# key_manager: IP-XACT component
VLNV tenstorrent.com:ocah:key_manager:1.0

## Address spaces and blocks
key_manager.rom: base 'h0, range 'h4000, width 32, memory
key_manager.sram: base 'h8000, range 'h8000, width 32, memory
key_manager.mailbox_km: base 'h10000, range 'h1c, width 32
key_manager.otp_efuse_map: base 'h11000, range 'h400, width 256
key_manager.otp_efuse_ctrl: base 'h11400, range 'h24, width 32
key_manager.otp_efuse_mmr: base 'h11500, range 'h74, width 32
key_manager.kpv: base 'h12000, range 'h1108, width 32
key_manager.kmcsr: base 'h14000, range 'h4c0, width 32
key_manager.drbg_sampler: base 'h15000, range 'h10, width 32
key_manager.otbn_wrapper_key: base 'h18000, range 'h64, width 32
key_manager.aes_wrapper_key: base 'h19000, range 'h44, width 32
key_manager.kmac_wrapper_key: base 'h1a000, range 'h44, width 32
key_manager.hmac_wrapper_key: base 'h1b000, range 'h44, width 32
key_manager.abr_wrapper_key: base 'h1c000, range 'h42c, width 32

## Registers
Registers are 32-bit, read-only, no defined reset value unless marked. A register's access mark holds for its fields unless they carry their own. Offsets are from the block's base; lines under a group give offsets from that group; [hi:lo] are bit positions; {n}, {i} and the like mark numbered series; 'fields as' and 'values as' point back to an identical list; <NAME> marks a mode.

## key_manager.mailbox_km — Register interface for KM CPU to access mailbox (write to outbound FIFO, read from inbound FIFO)
Base 0x00010000
0x00 KM_WRITE_DATA wo reset 0x0 — Write data to outbound FIFO (KM→SEP messages)
  [31:0] data — 32-bit data word to write to outbound FIFO
0x04 KM_WRITE_SEPARATOR access per field reset 0x0 — Write 1 to set message separator on next outbound (KM→SEP) write. Cleared by hardware when that write completes.
  [0] set rw — Write 1 to set message separator on next outbound write. Cleared by hardware when that write completes.
0x08 KM_READ_DATA reset 0x0 — Read data from inbound FIFO (SEP→KM messages)
  [31:0] data — 32-bit data word read from inbound FIFO
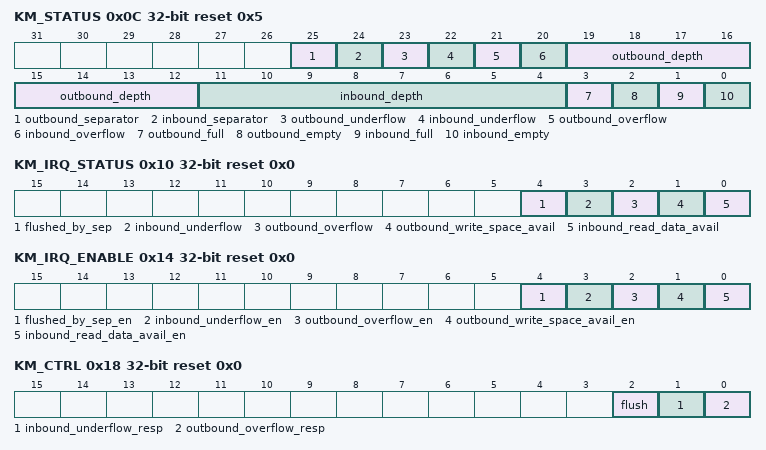
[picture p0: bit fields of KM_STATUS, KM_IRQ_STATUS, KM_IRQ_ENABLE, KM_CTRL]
0x0C KM_STATUS access per field reset 0x5 — FIFO status information
  [25] outbound_separator ro — Message separator: 1 if the last word read from outbound FIFO had the separator bit set (last word of message). Read-only, not sticky.
  [24] inbound_separator ro — Message separator: 1 if the last word read from inbound FIFO had the separator bit set (last word of message). Read-only, not sticky.
  [23] outbound_underflow rw write-1-clears — Outbound FIFO underflow detected (read attempted when empty). Sticky, write 1 to clear.
  [22] inbound_underflow rw write-1-clears — Inbound FIFO underflow detected (read attempted when empty). Sticky, write 1 to clear.
  [21] outbound_overflow rw write-1-clears — Outbound FIFO overflow detected (write attempted when full). Sticky, write 1 to clear.
  [20] inbound_overflow rw write-1-clears — Inbound FIFO overflow detected (write attempted when full). Sticky, write 1 to clear.
  [19:12] outbound_depth ro — Outbound FIFO fill level (number of words in FIFO)
  [11:4] inbound_depth ro — Inbound FIFO fill level (number of words in FIFO)
  [3] outbound_full ro — Outbound FIFO is full (cannot write more data)
  [2] outbound_empty ro — Outbound FIFO is empty (no data available for SEP to read)
  [1] inbound_full ro — Inbound FIFO is full
  [0] inbound_empty ro — Inbound FIFO is empty (no data available for KM to read)
0x10 KM_IRQ_STATUS access per field reset 0x0 — Interrupt status register
  [4] flushed_by_sep rw write-1-clears — SEP performed a mailbox flush. Sticky, write 1 to clear.
  [3] inbound_underflow rw write-1-clears — Inbound FIFO underflow detected. Sticky, write 1 to clear.
  [2] outbound_overflow rw write-1-clears — Outbound FIFO overflow detected. Sticky, write 1 to clear.
  [1] outbound_write_space_avail ro — Outbound FIFO has space available for KM to write (level-sensitive). 1 = space available, 0 = full.
  [0] inbound_read_data_avail ro — Inbound FIFO has data available for KM to read (level-sensitive). 1 = data available, 0 = empty.
0x14 KM_IRQ_ENABLE access per field reset 0x0 — Interrupt enable register for KM CPU
  [4] flushed_by_sep_en rw — Enable interrupt to KM when SEP performs a mailbox flush
  [3] inbound_underflow_en rw — Enable interrupt to KM when inbound FIFO underflow is detected
  [2] outbound_overflow_en rw — Enable interrupt to KM when outbound FIFO overflow is detected
  [1] outbound_write_space_avail_en rw — Enable interrupt to KM when outbound FIFO has space available (KM->SEP messages)
  [0] inbound_read_data_avail_en rw — Enable interrupt to KM when inbound FIFO has data available (SEP->KM messages)
0x18 KM_CTRL access per field reset 0x0 — Control register for mailbox behavior configuration
  [2] flush rw — Write 1 to flush all mailbox FIFOs (inbound and outbound). Cleared by hardware when flush completes.
  [1] inbound_underflow_resp rw — Response type for inbound FIFO underflow: 0=SLVERR (default), 1=OKAY
  [0] outbound_overflow_resp rw — Response type for outbound FIFO overflow: 0=SLVERR (default), 1=OKAY

## key_manager.otp_efuse_map — Per-field write-lock and read-lock registers for the SEP eFuse map.
Base 0x00011000
0x00 LOCKS 64-bit rw reset 0x0
  [63] SEP_SYS_ID_READ_LOCK write-1-sets — sep_sys_id_read_lock (slot 31): when set, SEP_SYS_ID is not read-able.
  [62] SEP_SYS_ID_WRITE_LOCK write-1-sets — sep_sys_id_write_lock (slot 31): when set, SEP_SYS_ID is not write-able.
  [61] SEP_SIP_ID_READ_LOCK write-1-sets — sep_sip_id_read_lock (slot 30): when set, SEP_SIP_ID is not read-able.
  [60] SEP_SIP_ID_WRITE_LOCK write-1-sets — sep_sip_id_write_lock (slot 30): when set, SEP_SIP_ID is not write-able.
  [59] SEP_CHIPLET_ID_READ_LOCK write-1-sets — sep_chiplet_id_read_lock (slot 29): when set, SEP_CHIPLET_ID is not read-able.
  [58] SEP_CHIPLET_ID_WRITE_LOCK write-1-sets — sep_chiplet_id_write_lock (slot 29): when set, SEP_CHIPLET_ID is not write-able.
  [57] SIP_PUBK_PQC_HASH1_READ_LOCK write-1-sets — sip_pubk_pqc_hash1_read_lock, when set, this field is not read-able (neither the eFuse nor the shadow register)
  [56] SIP_PUBK_PQC_HASH1_WRITE_LOCK write-1-sets — sip_pubk_pqc_hash1_write_lock, when set, this field is not write-able (neither the eFuse nor the shadow register)
  [55] SIP_PUBK_HASH1_READ_LOCK write-1-sets — sip_pubk_hash1_read_lock, when set, this field is not read-able (neither the eFuse nor the shadow register)
  [54] SIP_PUBK_HASH1_WRITE_LOCK write-1-sets — sip_pubk_hash1_write_lock, when set, this field is not write-able (neither the eFuse nor the shadow register)
  [53] SYS_PUBK_PQC_HASH_READ_LOCK write-1-sets — sys_pubk_pqc_hash_read_lock, when set, this field is not read-able (neither the eFuse nor the shadow register)
  [52] SYS_PUBK_PQC_HASH_WRITE_LOCK write-1-sets — sys_pubk_pqc_hash_write_lock, when set, this field is not write-able (neither the eFuse nor the shadow register)
  [51] SIP_PUBK_PQC_HASH0_READ_LOCK write-1-sets — sip_pubk_pqc_hash0_read_lock, when set, this field is not read-able (neither the eFuse nor the shadow register)
  [50] SIP_PUBK_PQC_HASH0_WRITE_LOCK write-1-sets — sip_pubk_pqc_hash0_write_lock, when set, this field is not write-able (neither the eFuse nor the shadow register)
  [49] CHIPLET_PUBK_PQC_HASH1_READ_LOCK write-1-sets — chiplet_pubk_pqc_hash1_read_lock, when set, this field is not read-able (neither the eFuse nor the shadow register)
  [48] CHIPLET_PUBK_PQC_HASH1_WRITE_LOCK write-1-sets — chiplet_pubk_pqc_hash1_write_lock, when set, this field is not write-able (neither the eFuse nor the shadow register)
  [47] CHIPLET_PUBK_PQC_HASH0_READ_LOCK write-1-sets — chiplet_pubk_pqc_hash0_read_lock, when set, this field is not read-able (neither the eFuse nor the shadow register)
  [46] CHIPLET_PUBK_PQC_HASH0_WRITE_LOCK write-1-sets — chiplet_pubk_pqc_hash0_write_lock, when set, this field is not write-able (neither the eFuse nor the shadow register)
  [45] REQUIRED_ALGS_READ_LOCK write-1-sets — required_algs_read_lock, when set, this field is not read-able (neither the eFuse nor the shadow register)
  [44] REQUIRED_ALGS_WRITE_LOCK write-1-sets — required_algs_write_lock, when set, this field is not write-able (neither the eFuse nor the shadow register)
  [43] REQUIRED_SIGNERS_READ_LOCK write-1-sets — required_signers_read_lock, when set, this field is not read-able (neither the eFuse nor the shadow register)
  [42] REQUIRED_SIGNERS_WRITE_LOCK write-1-sets — required_signers_write_lock, when set, this field is not write-able (neither the eFuse nor the shadow register)
  [41] CHIPLET_PUBK_HASH1_READ_LOCK write-1-sets — chiplet_pubk_hash1_read_lock, when set, this field is not read-able (neither the eFuse nor the shadow register)
  [40] CHIPLET_PUBK_HASH1_WRITE_LOCK write-1-sets — chiplet_pubk_hash1_write_lock, when set, this field is not write-able (neither the eFuse nor the shadow register)
  [39] CHIPLET_PUBK_HASH0_READ_LOCK write-1-sets — chiplet_pubk_hash0_read_lock, when set, this field is not read-able (neither the eFuse nor the shadow register)
  [38] CHIPLET_PUBK_HASH0_WRITE_LOCK write-1-sets — chiplet_pubk_hash0_write_lock, when set, this field is not write-able (neither the eFuse nor the shadow register)
  [37] SYSCLK_FREQ_MHZ_READ_LOCK write-1-sets — sysclk_freq_mhz_read_lock, when set, this field is not read-able (neither the eFuse nor the shadow register)
  [36] SYSCLK_FREQ_MHZ_WRITE_LOCK write-1-sets — sysclk_freq_mhz_write_lock, when set, this field is not write-able (neither the eFuse nor the shadow register)
  [35] ROM_CTL_READ_LOCK write-1-sets — rom_ctl_read_lock, when set, this field is not read-able (neither the eFuse nor the shadow register)
  [34] ROM_CTL_WRITE_LOCK write-1-sets — rom_ctl_write_lock, when set, this field is not write-able (neither the eFuse nor the shadow register)
  [33] STATUS_RPT_READ_LOCK write-1-sets — status_rpt_read_lock, when set, this field is not read-able (neither the eFuse nor the shadow register)
  [32] STATUS_RPT_WRITE_LOCK write-1-sets — status_rpt_write_lock, when set, this field is not write-able (neither the eFuse nor the shadow register)
  [31] SYS_UID_READ_LOCK write-1-sets — sys_uid_read_lock, when set, this field is not read-able (neither the eFuse nor the shadow register)
  [30] SYS_UID_WRITE_LOCK write-1-sets — sys_uid_write_lock, when set, this field is not write-able (neither the eFuse nor the shadow register)
  [29] SYS_PUBK_HASH_READ_LOCK write-1-sets — sys_pubk_hash_read_lock, when set, this field is not read-able (neither the eFuse nor the shadow register)
  [28] SYS_PUBK_HASH_WRITE_LOCK write-1-sets — sys_pubk_hash_write_lock, when set, this field is not write-able (neither the eFuse nor the shadow register)
  [27] SIP_UID_READ_LOCK write-1-sets — sip_uid_read_lock, when set, this field is not read-able (neither the eFuse nor the shadow register)
  [26] SIP_UID_WRITE_LOCK write-1-sets — sip_uid_write_lock, when set, this field is not write-able (neither the eFuse nor the shadow register)
  [25] SIP_PUBK_HASH0_READ_LOCK write-1-sets — sip_pubk_hash0_read_lock, when set, this field is not read-able (neither the eFuse nor the shadow register)
  [24] SIP_PUBK_HASH0_WRITE_LOCK write-1-sets — sip_pubk_hash0_write_lock, when set, this field is not write-able (neither the eFuse nor the shadow register)
  [23] CHIPLET_UID_READ_LOCK write-1-sets — chiplet_uid_read_lock, when set, this field is not read-able (neither the eFuse nor the shadow register)
  [22] CHIPLET_UID_WRITE_LOCK write-1-sets — chiplet_uid_write_lock, when set, this field is not write-able (neither the eFuse nor the shadow register)
  [21] BL2_VERSION_READ_LOCK write-1-sets — bl2_version_read_lock, when set, this field is not read-able (neither the eFuse nor the shadow register)
  [20] BL2_VERSION_WRITE_LOCK write-1-sets — bl2_version_write_lock, when set, this field is not write-able (neither the eFuse nor the shadow register)
  [19] BL1_VERSION_READ_LOCK write-1-sets — bl1_version_read_lock, when set, this field is not read-able (neither the eFuse nor the shadow register)
  [18] BL1_VERSION_WRITE_LOCK write-1-sets — bl1_version_write_lock, when set, this field is not write-able (neither the eFuse nor the shadow register)
  [17] CHIPLET_PUBK_REVOKE_READ_LOCK write-1-sets — chiplet_pubk_revoke_read_lock, when set, this field is not read-able (neither the eFuse nor the shadow register)
  [16] CHIPLET_PUBK_REVOKE_WRITE_LOCK write-1-sets — chiplet_pubk_revoke_write_lock, when set, this field is not write-able (neither the eFuse nor the shadow register)
  [15] CLASS_KEY_READ_LOCK write-1-sets — class_key_read_lock, when set, this field is not read-able (neither the eFuse nor the shadow register)
  [14] CLASS_KEY_WRITE_LOCK write-1-sets — class_key_write_lock, when set, this field is not write-able (neither the eFuse nor the shadow register)
  [13] RMA_CHIPLET_TOKEN_DIGEST_READ_LOCK write-1-sets — rma_chiplet_token_digest_read_lock, when set, this field is not read-able (neither the eFuse nor the shadow register)
  [12] RMA_CHIPLET_TOKEN_DIGEST_WRITE_LOCK write-1-sets — rma_chiplet_token_digest_write_lock, when set, this field is not write-able (neither the eFuse nor the shadow register)
  [11] RMA_SIP_TOKEN_DIGEST_READ_LOCK write-1-sets — rma_sip_token_digest_read_lock, when set, this field is not read-able (neither the eFuse nor the shadow register)
  [10] RMA_SIP_TOKEN_DIGEST_WRITE_LOCK write-1-sets — rma_sip_token_digest_write_lock, when set, this field is not write-able (neither the eFuse nor the shadow register)
  [9] SYS_DIS_READ_LOCK write-1-sets — sys_dis_read_lock, when set, this field is not read-able (neither the eFuse nor the shadow register)
  [8] SYS_DIS_WRITE_LOCK write-1-sets — sys_dis_write_lock, when set, this field is not write-able (neither the eFuse nor the shadow register)
  [7] SIP_DIS_READ_LOCK write-1-sets — sip_dis_read_lock, when set, this field is not read-able (neither the eFuse nor the shadow register)
  [6] SIP_DIS_WRITE_LOCK write-1-sets — sip_dis_write_lock, when set, this field is not write-able (neither the eFuse nor the shadow register)
  [5] TRANSIENT_RMA_EN_READ_LOCK write-1-sets — TRANSIENT_RMA_EN_READ_LOCK, when set, this field is not read-able (neither the eFuse nor the shadow register)
  [4] TRANSIENT_RMA_EN_WRITE_LOCK write-1-sets — TRANSIENT_RMA_EN_WRITE_LOCK, when set, this field is not write-able (neither the eFuse nor the shadow register)
  [3] SBOOT_DIS_READ_LOCK write-1-sets — sboot_dis_read_lock, when set, this field is not read-able (neither the eFuse nor the shadow register)
  [2] SBOOT_DIS_WRITE_LOCK write-1-sets — sboot_dis_write_lock, when set, this field is not write-able (neither the eFuse nor the shadow register)
  [1] LC_STATE_READ_LOCK write-1-sets — lc_state_read_lock, when set, this field is not read-able (neither the eFuse nor the shadow register)
  [0] LC_STATE_WRITE_LOCK write-1-sets — lc_state_write_lock, when set, this field is not write-able (neither the eFuse nor the shadow register)
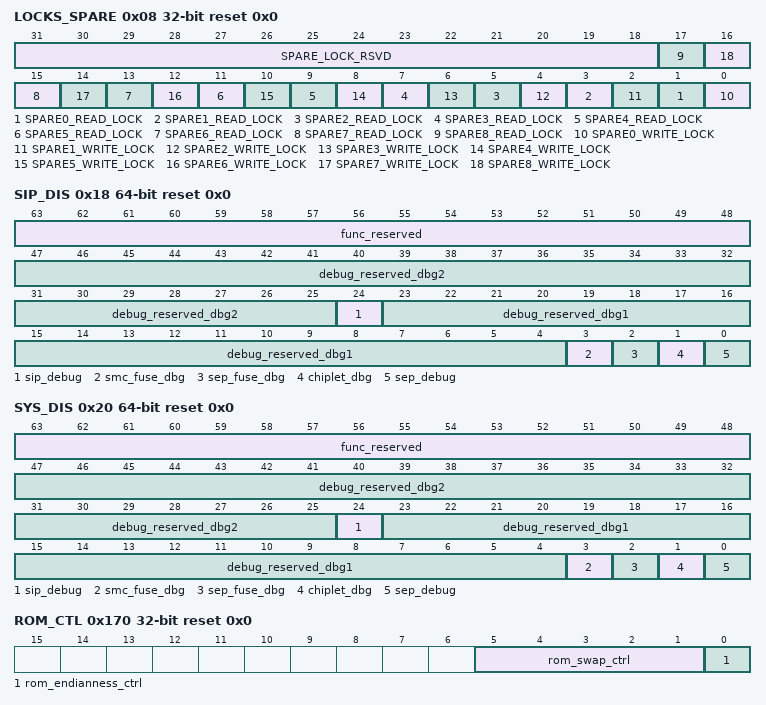
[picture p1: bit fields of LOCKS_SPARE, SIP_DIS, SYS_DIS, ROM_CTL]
0x08 LOCKS_SPARE rw reset 0x0
  [31:18] SPARE_LOCK_RSVD write-1-sets — Unassigned lock slots 41-47. Reserved for future field lock assignments.
  [2n+1] SPARE{n}_READ_LOCK write-1-sets (n=0..8) — spare{n}_read_lock (slot {n+32}): when set, spare{n} is not read-able.
  [2n] SPARE{n}_WRITE_LOCK write-1-sets (n=0..8) — spare{n}_write_lock (slot {n+32}): when set, spare{n} is not write-able.
0x0C LC_STATE reset 0xF
  [7:0] lc_state — Life cycle manufacturing state, differentially encoded: {~raw[3:0], raw[3:0]}
0x10 SBOOT_DIS reset 0x0
  [0] disable_secure_boot — Chicken bit to disable secure boot in SEP ROM.
0x14 TRANSIENT_RMA_EN reset 0x0
  [0] transient_rma_en — When Transient RMA EN is 1, matching on corresponding *_Tokens will automatically transfer the chip to the corresponding RMA state by setting the LC_STATE reg
0x18 SIP_DIS 64-bit rw reset 0x0 — An owner's feature control vector. When set (1'b1), the corresponding feature is disabled. Layout: see the Disable Vector Format section of lifecycle_controller.adoc.
  [63:48] func_reserved write-1-sets — Reserved for adopter-defined functional feature gating (bits 63:48).
  [47:25] debug_reserved_dbg2 write-1-sets — Reserved for adopter-defined inter-chiplet-bypass (DBG_2) debug scan chains (bits 47:25).
  [24] sip_debug write-1-sets — SIP_DBG (bit 24): Coarse-grained debug enable for the SiP scope: the inter-chiplet debug-bypass gate that admits external (PTAP) debug traffic into this chiplet and forwards it onward to the next chiplet via the outbound JTAG PTAP. 1'b1: disabled. 1'b0: enabled.
  [23:4] debug_reserved_dbg1 write-1-sets — Reserved for adopter-defined local (DBG_1) debug scan chains (bits 23:4).
  [3] smc_fuse_dbg write-1-sets — SMC_FUSE_DBG (bit 3): 1'b1: the DFT-inserted access path into the SMC OTP is disabled. 1'b0: enabled. Produced by SEP-LCC feat_ctrl_o, exported on the SEP boundary, and consumed by SMC to gate its own inserted fuse path.
  [2] sep_fuse_dbg write-1-sets — SEP_FUSE_DBG (bit 2): 1'b1: the DFT-inserted access path into the SEP OTP is disabled. 1'b0: enabled. Also covers the OTP IP-vendor test and calibration interface, which is reachable only over that inserted path. The functional JTAG2AXIL path to the OTP is always available and is not gated by this bit.
  [1] chiplet_dbg write-1-sets — CHIPLET_DBG (bit 1): Coarse-grained debug enable for the chiplet scope. 1'b1: chiplet-scope debug/scan-dump access disabled. 1'b0: enabled. Never acts alone: an external debugger reaches chiplet-internal resources only when SIP_DBG is open as well. Contributes to the reachability of the crypto/KM secure chain but never authorizes a dump from it.
  [0] sep_debug write-1-sets — SEP_DBG (bit 0): Coarse-grained debug enable for the SEP scope. 1'b1: SEP-scope debug/scan-dump access disabled and external inbound traffic is filtered. 1'b0: enabled. A local gate only: reaching SEP internal state from an external debugger additionally requires SIP_DBG and CHIPLET_DBG.
0x20 SYS_DIS 64-bit rw reset 0x0 — An owner's feature control vector. When set (1'b1), the corresponding feature is disabled. Layout: see the Disable Vector Format section of lifecycle_controller.adoc.
  fields as SIP_DIS
0x28 RMA_SIP_TOKEN_DIGEST 256-bit reset 0x0
  [255:0] token_digest — Hash digest of life cycle secret that allows entering RMA_SIP state / Note this is a 256 bit field
0x48 RMA_CHIPLET_TOKEN_DIGEST 256-bit reset 0x0
  [255:0] token_digest — Hash digest of life cycle secret that allows entering RMA_CHIPLET state/ Note this is a 256 bit field
0x68 CLASS_KEY 256-bit reset 0x0
  [255:0] key — Class key that could be used for FW encryption/decryption
0x88 CHIPLET_PUBK_REVOKE reset 0x0
  [31:0] select — Global public-key revocation vector covering every boot-verification key of every owner (classical and PQC). SEP ROM embeds a set of public-key hash digests and accesses additional fused key hashes; each key entry maps to one bit here. Once set, SEP ROM rejects the corresponding key. Bit map: [7:0] ROM chiplet-creator classical keys (bits 0,1 are development keys); [15:8] ROM chiplet-creator PQC keys; [16]/[17] CHIPLET_PUBK_HASH0/1; [18]/[19] CHIPLET_PUBK_PQC_HASH0/1; [20]/[21] SIP_PUBK_HASH0 / SIP_PUBK_PQC_HASH0; [22]/[23] SYS_PUBK_HASH / SYS_PUBK_PQC_HASH; [24]/[25] SIP_PUBK_HASH1 / SIP_PUBK_PQC_HASH1; [31:26] reserved. Before the chiplet owner transfers a part to the customer, the development-key bits shall be set (revoked).
0x8C BL1_VERSION 256-bit reset 0x0
  [255:0] version — Minimum BL1 version that can be loaded by SEPROM
0xAC BL2_VERSION 256-bit reset 0x0
  [255:0] version — Minimum BL2 version that can be loaded by BL1. If more boot stages exist, rollback protection can be implemented by BL2.
0xCC CHIPLET_UID 256-bit reset 0x0
  [255:0] uid — Silicon creator's secret device unique ID (also referred to as UDS - Unique Device Secret). The chiplet creator is responsible for CHIPLET_UID provisioning and public identity enrollment. When read-locked, both writability and software visibility are disabled.
0xEC SIP_PUBK_HASH0 256-bit reset 0x0
  [255:0] key_hash — Hash digest of SiP owner's root public key for secure boot. The chiplet creator's actual root public key is embedded in the SEPROM; this digest is used to validate that public key.
0x10C SIP_UID 256-bit reset 0x0
  [255:0] uid — SiP owner's secret device unique ID. The SiP owner is responsible for SIP_UID provisioning and public identity enrollment. When read-locked, both writability and software visibility are disabled.
0x12C SYS_PUBK_HASH 256-bit reset 0x0
  [255:0] key_hash — Hash digest of system owner's root public key for secure boot.
0x14C SYS_UID 256-bit reset 0x0
  [255:0] uid — System owner's secret device unique ID. The system owner is responsible for SYS_UID provisioning and public identity enrollment. When read-locked, both writability and software visibility are disabled.
0x16C STATUS_RPT reset 0x0
  [1:0] rpt — BOOTROM report status based on the bit. 2'b00-> bootrom report status based on GPIO; 2'b01->bootrom report status;otherwise, bootrom does not report status
0x170 ROM_CTL reset 0x0
  [5:1] rom_swap_ctrl — controls how the rom slices are swapped
  [0] rom_endianness_ctrl — controls the endianness of the rom data out. 0->little endian; 1->big endian
0x174 SYSCLK_FREQ_MHZ reset 0x0
  [10:0] sysclk_freq_mhz — Configured sysclk PLL frequency in MHz; ignored if 0. Consumed by boot ROM clock math.
0x178 CHIPLET_PUBK_HASH0 256-bit reset 0x0
  [255:0] key_hash — Chiplet owner authentication key hash digest, fused. These chiplet owner fused key hashes can be used in addition to the hashes in the ROM itself to authenticate manifests.
0x198 CHIPLET_PUBK_HASH1 256-bit reset 0x0
  fields as CHIPLET_PUBK_HASH0
0x1B8 REQUIRED_SIGNERS access per field reset 0x0
  [1:0] required_signers rw write-1-sets — Owners whose signature is required to authenticate any image loadable by SEP ROM. Per owner, 1 = required, 0 = not-required; the default all-zero value requires no additional owner. [0] SiP owner, [1] system owner. The chiplet creator is the root of trust and always authenticates BL1, so it has no bit here.
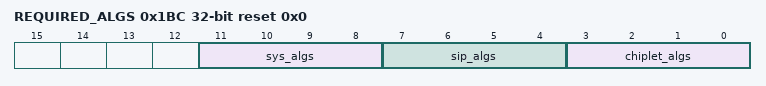
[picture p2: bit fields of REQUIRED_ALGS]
0x1BC REQUIRED_ALGS access per field reset 0x0
  [11:8] sys_algs rw write-1-sets — Per-owner required signature algorithms for system owner. bit 0 = classical, bit 1 = post-quantum (ML-DSA), bits 3:2 reserved.
  [7:4] sip_algs rw write-1-sets — Per-owner required signature algorithms for SiP owner. bit 0 = classical, bit 1 = post-quantum (ML-DSA), bits 3:2 reserved.
  [3:0] chiplet_algs rw write-1-sets — Per-owner required signature algorithms for chiplet. Each nibble: bit 0 = classical (ECDSA P-384 or RSA), bit 1 = post-quantum (ML-DSA), bits 3:2 reserved.
0x1C0 CHIPLET_PUBK_PQC_HASH0 256-bit reset 0x0
  [255:0] key_hash — Chiplet owner ML-DSA PQC authentication key hash digest, fused. PQC counterpart of the corresponding CHIPLET_PUBK_HASH.
0x1E0 CHIPLET_PUBK_PQC_HASH1 256-bit reset 0x0
  fields as CHIPLET_PUBK_PQC_HASH0
0x200 SIP_PUBK_PQC_HASH0 256-bit reset 0x0
  [255:0] key_hash — Hash digest of the SiP owner's ML-DSA PQC root public key for secure boot. PQC counterpart of SIP_PUBK_HASH.
0x220 SYS_PUBK_PQC_HASH 256-bit reset 0x0
  [255:0] key_hash — Hash digest of the system owner's ML-DSA PQC root public key for secure boot. PQC counterpart of SYS_PUBK_HASH.
0x240 SIP_PUBK_HASH1 256-bit reset 0x0
  fields as SIP_PUBK_HASH0
0x260 SIP_PUBK_PQC_HASH1 256-bit reset 0x0
  fields as SIP_PUBK_PQC_HASH0
0x280 SEP_CHIPLET_ID 256-bit reset 0x0
  [255:0] id — Per-owner public identity fuse. Personalization input for the Key Manager identity root. Being public, no read protection is required. Individually lockable via LOCKS[58:63] (slots 29-31).
0x2A0 SEP_SIP_ID 256-bit reset 0x0
  fields as SEP_CHIPLET_ID
0x2C0 SEP_SYS_ID 256-bit reset 0x0
  fields as SEP_CHIPLET_ID
{0x2E0+0x20*i} spare{i} 256-bit reset 0x0 (i=0..8)
  [255:0] rsvd — Spare region for future use. Individually lockable via LOCKS_SPARE (slots 32-40).

## key_manager.otp_efuse_ctrl — Program and read command, address, data, status, and timeout registers for the eFuse interface.
Base 0x00011400
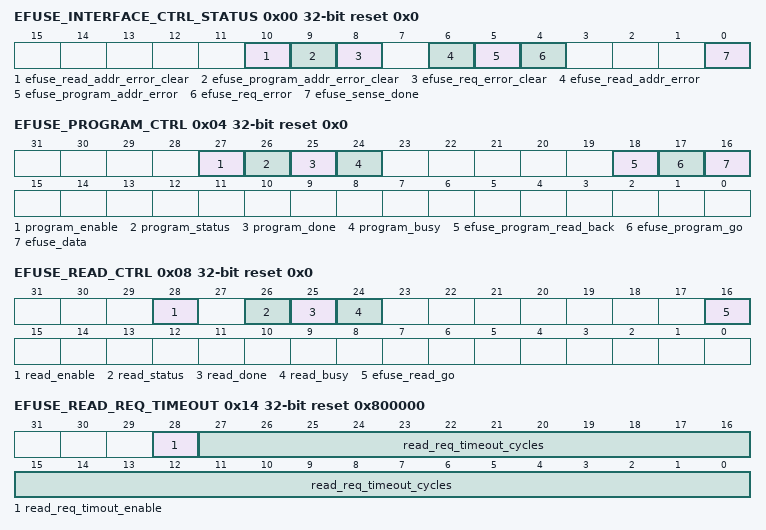
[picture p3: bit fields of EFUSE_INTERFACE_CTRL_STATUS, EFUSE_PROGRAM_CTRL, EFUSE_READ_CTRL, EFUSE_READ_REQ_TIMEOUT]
0x00 EFUSE_INTERFACE_CTRL_STATUS access per field reset 0x0 (reset mask 0x770) — eFuse interface status and error-clear register. Reports the sense-done flag and request/address error conditions, and provides write-1 strobes to clear those errors.
  [10] efuse_read_addr_error_clear wo — Clears the read out of bounds error bit (efuse_read_addr_error) in efuse_ctrl_status
  [9] efuse_program_addr_error_clear wo — Clears the program out of bounds error bit (efuse_program_addr_error) in efuse_ctrl_status
  [8] efuse_req_error_clear wo — Clears the blocked request error bit in efuse_ctrl_status
  [6] efuse_read_addr_error ro — Indicates that an invalid eFuse read address was used (address exceeds the implemented eFuse size). The error must be cleared by writing 1 to efuse_read_addr_error_clear.
  [5] efuse_program_addr_error ro — Indicates that an invalid eFuse program address was used (address exceeds the implemented eFuse size). The error must be cleared by writing 1 to efuse_program_addr_error_clear.
  [4] efuse_req_error ro — Indicates that the eFuse was blocked because of either read or a program lock. The error must be cleared by writing 1 to efuse_req_error_clear to this register
  [0] efuse_sense_done ro — Indicates if the eFuse state machine has completed
0x04 EFUSE_PROGRAM_CTRL access per field reset 0x0 — eFuse program control and status. Configures the program data, triggers a program of the bit at EFUSE_PROGRAM_ADDR (optionally with read-back), and reports program progress and completion status.
  [27] program_enable rw — When set, enables the program request
  [26] program_status ro — 0: No Error. 1: Error
  [25] program_done ro — When set, the program has completed, the status of which is in program_status
  [24] program_busy ro — When set, the program is in progress
  [18] efuse_program_read_back rw — When set, trigger a read back after a program
  [17] efuse_program_go rw — When set, triggers a program to the eFuse. This will be ignored if the lock bit is set
  [16] efuse_data rw — Data to program to eFuse. If this bit is 0, the program request will be ignored
0x08 EFUSE_READ_CTRL access per field reset 0x0 — eFuse read control and status. Triggers a read of the word at EFUSE_READ_ADDR and reports read progress and completion status.
  [28] read_enable rw — When set, enables the read request
  [26] read_status ro — 0: No Error. 1: Error. Set when read_go is asserted while read is not enabled, the address is out of bounds, or the read request times out.
  [25] read_done ro — When set, the read has completed, the status of which is in read_status
  [24] read_busy ro — When set, the read is in progress
  [16] efuse_read_go rw — When set, triggers a read to efuse.
0x0C EFUSE_PROGRAM_INTERFACE_READ_DATA reset 0x0 — Read data captured through the program interface. Hardware debug only; valid only while the program interface state machine is in its capture-data state.
  [31:0] dout — Read Data from eFuse through program interface. This field is only valid when the efuse programming interface is utilized to burn the efuse IP and only when the state machine is during ST_CAPTUER_DATA state. Hardware debug only
0x10 EFUSE_READ_INTERFACE_READ_DATA reset 0x0 — Read data returned through the eFuse read interface.
  [31:0] dout — Read Data from eFuse through READ interface.
0x14 EFUSE_READ_REQ_TIMEOUT rw reset 0x800000 — Read interface timeout configuration. Sets the number of cycles the read interface waits for a SHIM response and enables the read timeout.
  [28] read_req_timout_enable — Enable timeout on read interface
  [27:0] read_req_timeout_cycles — Number of cycles the read interface will wait for a response from the shim. At 100MHz this can count ~= 2.5 seconds.
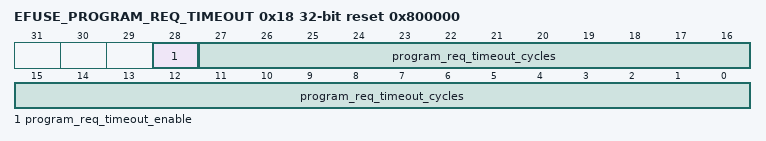
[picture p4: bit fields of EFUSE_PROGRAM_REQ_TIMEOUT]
0x18 EFUSE_PROGRAM_REQ_TIMEOUT rw reset 0x800000 — Program interface timeout configuration. Sets the number of cycles the program interface waits for a SHIM response and enables the program timeout.
  [28] program_req_timeout_enable — Enable timeout on program interface.
  [27:0] program_req_timeout_cycles — Number of cycles the program interface will wait for a response from the shim. At 100MHz this can count ~= 2.5 seconds.
0x1C EFUSE_PROGRAM_ADDR rw reset 0x0 — Bit address for the next program. Set it before EFUSE_PROGRAM_CTRL.efuse_program_go.
  [31:0] efuse_addr — Bit address to program. Writing this register does not check the address; a program started with an address at or beyond the implemented eFuse size is not issued and sets efuse_program_addr_error.
0x20 EFUSE_READ_ADDR rw reset 0x0 — Bit address for the next read. Set it before EFUSE_READ_CTRL.efuse_read_go.
  [31:0] efuse_addr — Bit address of the word to read. Writing this register does not check the address; a read started with an address at or beyond the implemented eFuse size is not issued and sets efuse_read_addr_error.

## key_manager.otp_efuse_mmr — Security-token input and match-status registers for RMA and secure-disable eFuse tokens.
Base 0x00011500
{0x0+4i} RMA_SIP_TOKEN_I[{i}] (i=0..7) rw — Software-writeable RMA token word. The assembled token is hashed and compared against the fused value to authorize lifecycle (LC) state transitions.
  [31:0] token — Portion of writeable version of RMA_*_TOKEN, hashed, and compared with fused value to allow LC to change states.
{0x20+4i} RMA_CHIPLET_TOKEN_I[{i}] (i=0..7) rw — Software-writeable RMA token word. The assembled token is hashed and compared against the fused value to authorize lifecycle (LC) state transitions.
  fields as RMA_SIP_TOKEN_I[0]
{0x40+4i} SEC_DISABLE_TOKEN_I[{i}] (i=0..7) rw — Software-writeable security-disable token word. The assembled token is hashed and compared against the post-silicon injected value to authorize security_disable.
  [31:0] token — Portion of writeable version of SEC_DISABLE_TOKEN, hashed, and compared with the post silicon injected values to allow security_disable.
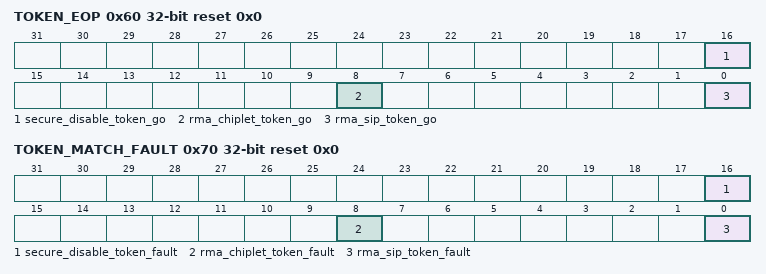
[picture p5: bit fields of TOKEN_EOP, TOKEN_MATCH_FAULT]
0x60 TOKEN_EOP wo reset 0x0 — Token end-of-packet control. Writing the per-token go bit signals that all token words have been written and triggers a pulse to begin token hashing.
  [16] secure_disable_token_go — Write 1 to indicate that all token data has been written; this generates a pulse to begin token hashing.
  [8] rma_chiplet_token_go — Write 1 to indicate that all token data has been written; this generates a pulse to begin token hashing.
  [0] rma_sip_token_go — Write 1 to indicate that all token data has been written; this generates a pulse to begin token hashing.
0x64 RMA_SIP_TOKEN_MATCH reset 0x0 — Token match status. Reports the result of the token hash comparison (match, mismatch, or error).
  [5:0] token_match_status — Store the status of the token match. Match = 6'b010101, Mismatch = 6'b101010, Error = 6'b111111
0x68 RMA_CHIPLET_TOKEN_MATCH reset 0x0 — Token match status. Reports the result of the token hash comparison (match, mismatch, or error).
  fields as RMA_SIP_TOKEN_MATCH
0x6C SEC_DISABLE_TOKEN_MATCH reset 0x0 — Token match status. Reports the result of the token hash comparison (match, mismatch, or error).
  fields as RMA_SIP_TOKEN_MATCH
0x70 TOKEN_MATCH_FAULT reset 0x0 — Token comparator redundancy fault status. The token match logic is triple redundant and is not a majority vote: all three comparators must agree and each must drive a legal differential pair. A bit sets when the comparators for that token disagree, which may indicate a fault injection or FIB attack. The corresponding token_match_status then reads the error code 6'b111111 and an interrupt is raised to the SEP CPU. Bits are sticky until reset.
  [16] secure_disable_token_fault — A redundancy fault was detected in the SEC_DISABLE_TOKEN comparators.
  [8] rma_chiplet_token_fault — A redundancy fault was detected in the RMA_CHIPLET_TOKEN comparators.
  [0] rma_sip_token_fault — A redundancy fault was detected in the RMA_SIP_TOKEN comparators.

## key_manager.kpv — Key entry storage and KM control registers. Access conditioned by lock_write/lock_use.
Base 0x00012000
{0x0+0x40*i} KEY_ENTRY[{i}] (i=0..63) group — One key entry (16 x 32-bit words = 512 bits)
  {0x0+4j} WORD[{j}] (j=0..15) rw — One 32-bit word of a key entry (512-bit key = 16 words). No reset; powers up random.
    [31:0] data — 32-bit key data word. No reset for security; power-up value undefined. Actual storage is in km_kpv_regfile; CSR field is a protocol placeholder.
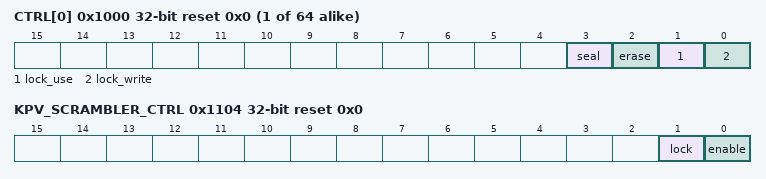
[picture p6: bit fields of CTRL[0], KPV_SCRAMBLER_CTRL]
{0x1000+4i} CTRL[{i}] (i=0..63) access per field reset 0x0 — Per-slot control: lock bits (W1S) and the erase trigger
  [3] seal rw write-1-sets — Seals this key entry until warm reset. Read-any, write-1-only. Setting this bit also sets lock_write in hardware, so a single write seals the slot: its data can be read but not overwritten. Erase remains available, and erasing a sealed slot retires it rather than freeing it (see ERASE), so a sealed slot's material can be destroyed but its slot never reused.
  [2] erase rw write-1-sets — Write-1 to start hardware erase of this slot: an LFSR fills all 16 key words (through the KPV scrambler). Hardware self-clears this bit when the erase completes. Never blocked: neither lock_write, lock_use nor seal prevents an erase. The slot's seal state when the erase completes decides the outcome. Unsealed, the slot CTRL register is cleared and the slot is reusable. Sealed, lock_write stays set and lock_use is set, retiring the slot: its data is destroyed and it can be neither read, rewritten nor reused until warm reset. A seal taken while an erase is already in flight therefore still retires the slot.
  [1] lock_use rw write-1-sets — Prevents KM read of this key entry data until reset. Read-any, write-1-only. Hardware sets this bit when an erase of a sealed slot completes, retiring the slot: its destroyed contents cannot be read back.
  [0] lock_write rw write-1-sets — Prevents KM write to this key entry data until reset; this register stays writable so that a locked slot can still be read-locked and erased. Read-any, write-1-only. Hardware holds this bit set for as long as SEAL is set, so sealing a slot write-locks it without a separate write here.
0x1100 KPV_SCRAMBLER_KEY rw — 32-bit key for KPV key entry scrambling. No reset; powers up random. Locked when KPV_SCRAMBLER_CTRL.LOCK=1.
  [31:0] key — Scrambler key. No reset for security. HW clears to 0 on wipe via hwclr.
0x1104 KPV_SCRAMBLER_CTRL access per field reset 0x0 — KPV scrambler enable and lock. Reset to 0 on KM reset. LOCK is write-one-only.
  [1] lock rw write-1-sets — Write-one-only. When 1, key and ENABLE cannot be modified until KM reset.
  [0] enable rw — 1 = scramble key entry data on write, descramble on read; 0 = passthrough.

## key_manager.kmcsr — Control and status registers for the Key Manager subsystem
Base 0x00014000
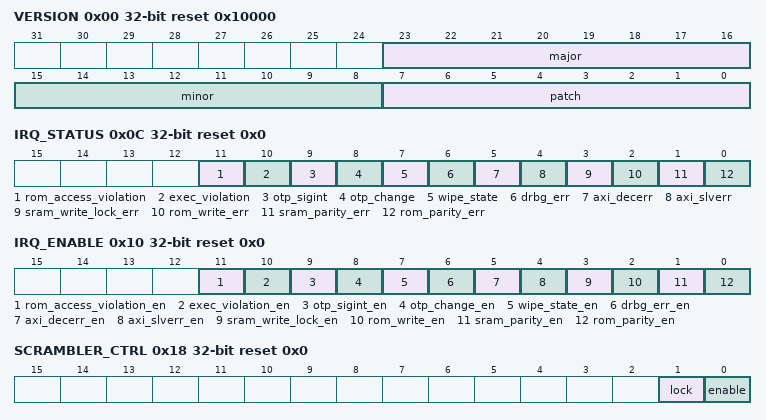
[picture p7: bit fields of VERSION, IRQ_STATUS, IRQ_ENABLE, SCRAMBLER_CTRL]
0x00 VERSION reset 0x10000 — Hardware version register (semantic versioning: major.minor.patch)
  [23:16] major — Major version number
  [15:8] minor — Minor version number
  [7:0] patch — Patch version number
0x04 CTRL reset 0x0 — Control register (reserved for future use)
0x08 SOFT_RST_CODE rw reset 0x0 — Software reset code register. Write 0x53525354 ('SRST') to trigger soft reset. Any other value has no effect.
  [31:0] code — 32-bit reset code. Write 0x53525354 to trigger soft reset.
0x0C IRQ_STATUS access per field reset 0x0 — Interrupt status register. Sticky bits cleared by writing 1.
  [11] rom_access_violation rw write-1-clears — KM ROM instruction fetch or data read attempted after the ROM lockout engaged. The lockout engages on the first committed instruction fetch from write-locked SRAM once SRAM_EXEC_MODE.enable is set, and clears only on warm or cold reset. Sticky, write 1 to clear.
  [10] exec_violation rw write-1-clears — Instruction fetch from a non-whitelisted (non-executable) memory region detected, excluding the KM ROM. Sticky, write 1 to clear.
  [9] otp_sigint rw write-1-clears — OTP dual-rail encoding integrity violation: value and complement are not complementary on at least one field. Sticky, write 1 to clear.
  [8] otp_change rw write-1-clears — An OTP readout field value changed (decoded value differs from prior cycle). Sticky, write 1 to clear. Check OTP_CHANGE_STATUS for the specific field(s).
  [7] wipe_state rw write-1-clears — Wipe state event (rising edge of wipe_state input). Sticky, write 1 to clear.
  [6] drbg_err rw write-1-clears — DRBG Sampler error (timeout or AXI-Stream error). Sticky, write 1 to clear.
  [5] axi_decerr rw write-1-clears — AXI DECERR (decode error) response detected on CPU bus transaction. Sticky, write 1 to clear.
  [4] axi_slverr rw write-1-clears — AXI SLVERR (slave error) response detected on CPU bus transaction. Sticky, write 1 to clear.
  [3] sram_write_lock_err rw write-1-clears — SRAM write attempt to a write-locked region detected. Sticky, write 1 to clear.
  [2] rom_write_err rw write-1-clears — ROM write attempt detected (ROM is read-only). Sticky, write 1 to clear.
  [1] sram_parity_err rw write-1-clears — SRAM parity error detected. Sticky, write 1 to clear.
  [0] rom_parity_err rw write-1-clears — ROM parity error detected. Sticky, write 1 to clear.
0x10 IRQ_ENABLE access per field reset 0x0 — Interrupt enable/mask register
  [11] rom_access_violation_en rw — Enable ROM lockout violation interrupt
  [10] exec_violation_en rw — Enable execute-permission whitelist violation interrupt
  [9] otp_sigint_en rw — Enable OTP dual-rail integrity violation interrupt
  [8] otp_change_en rw — Enable OTP field change interrupt
  [7] wipe_state_en rw — Enable wipe state interrupt
  [6] drbg_err_en rw — Enable DRBG Sampler error interrupt
  [5] axi_decerr_en rw — Enable AXI DECERR error interrupt
  [4] axi_slverr_en rw — Enable AXI SLVERR error interrupt
  [3] sram_write_lock_en rw — Enable SRAM write-lock violation interrupt
  [2] rom_write_en rw — Enable ROM write error interrupt
  [1] sram_parity_en rw — Enable SRAM parity error interrupt
  [0] rom_parity_en rw — Enable ROM parity error interrupt
0x14 SCRAMBLER_KEY rw — 32-bit scrambler key for SRAM address/data scrambling. When locked: writes ignored, reads return 0. No reset; powers up random.
  [31:0] key — Scrambler key value. Not readable when SCRAMBLER_CTRL.LOCK=1 (returns 0). No reset for security; power-up value undefined.
0x18 SCRAMBLER_CTRL access per field reset 0x0 — Scrambler control register
  [1] lock rw — Lock scrambler key and enable bit. Once set, key and enable cannot be modified until reset. Write-once (0->1 only). Security requirement: prevents disabling scrambling after key provisioning.
  [0] enable rw — Enable SRAM scrambling. When 0, data passes through unmodified. Locked when LOCK=1 (security requirement).
0x1C SRAM_LOCK rw reset 0x0 — SRAM write-lock bits. Bit[i]=1 locks region i (1 KB each, 32 regions). Write-1-only: writing 1 sets the bit, writing 0 has no effect. Cleared by warm or cold reset (warm reset domain); ROM re-applies the lock policy on every boot before handover to mutable firmware.
  [31:0] lock_bits write-1-sets — One bit per 1 KB SRAM region. Region 0 = 0x8000-0x83FF, region 31 = 0xFC00-0xFFFF. Write 1 to lock; 0 has no effect. Warm reset domain: cleared by warm or cold reset.
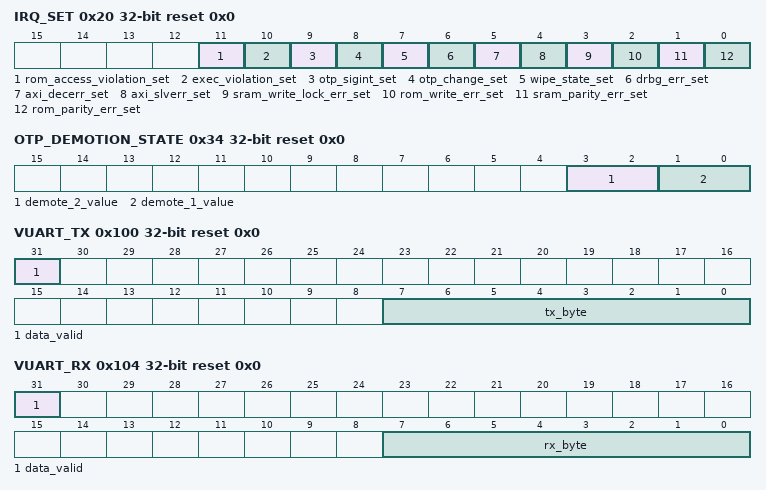
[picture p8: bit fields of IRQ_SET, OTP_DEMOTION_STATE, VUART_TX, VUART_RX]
0x20 IRQ_SET wo reset 0x0 — Interrupt set register. Write 1 to trigger corresponding interrupt (for ISR testing). Write-only, reads return 0.
  [11] rom_access_violation_set — Write 1 to set IRQ_STATUS.ROM_ACCESS_VIOLATION (triggers ROM lockout violation interrupt for testing)
  [10] exec_violation_set — Write 1 to set IRQ_STATUS.EXEC_VIOLATION (triggers exec-permission violation interrupt for testing)
  [9] otp_sigint_set — Write 1 to set IRQ_STATUS.OTP_SIGINT (triggers OTP sigint interrupt for testing)
  [8] otp_change_set — Write 1 to set IRQ_STATUS.OTP_CHANGE (triggers OTP change interrupt for testing)
  [7] wipe_state_set — Write 1 to set IRQ_STATUS.WIPE_STATE (triggers wipe state interrupt for testing)
  [6] drbg_err_set — Write 1 to set IRQ_STATUS.DRBG_ERR (triggers DRBG Sampler interrupt for testing)
  [5] axi_decerr_set — Write 1 to set IRQ_STATUS.AXI_DECERR (triggers AXI DECERR interrupt for testing)
  [4] axi_slverr_set — Write 1 to set IRQ_STATUS.AXI_SLVERR (triggers AXI SLVERR interrupt for testing)
  [3] sram_write_lock_err_set — Write 1 to set IRQ_STATUS.SRAM_WRITE_LOCK_ERR (triggers SRAM write-lock interrupt for testing)
  [2] rom_write_err_set — Write 1 to set IRQ_STATUS.ROM_WRITE_ERR (triggers ROM write interrupt for testing)
  [1] sram_parity_err_set — Write 1 to set IRQ_STATUS.SRAM_PARITY_ERR (triggers SRAM parity interrupt for testing)
  [0] rom_parity_err_set — Write 1 to set IRQ_STATUS.ROM_PARITY_ERR (triggers ROM parity interrupt for testing)
0x24 SRAM_WRITE_LOCK_VIOLATION rw reset 0x0 — Which SRAM region(s) had write attempts while locked. Bit[i]=region i. Sticky, write 1 to clear each bit.
  [31:0] violation_bits write-1-clears — Bit[i]=1 if region i had attempted write while locked. Sticky, write 1 to clear each bit.
0x28 RECOVERABLE_ERR access per field reset 0x0 — Recoverable error status. Firmware writes 1 to set (after recovering in ISR), writes 0 to clear (e.g. when SEP requests clear). Drives recoverable error event output.
  [0] recoverable_err rw — 1 = recoverable fault occurred and was handled by ISR; 0 = clear. Write 1 to set, write 0 to clear.
0x2C BOOT_STATUS access per field reset 0x0 — Boot status. Firmware writes 1 to COLD_BOOT_DONE after cold-boot init completes; bit remains set until next cold reset.
  [0] cold_boot_done rw write-1-sets — Write-1-only: set by ROM firmware at end of cold boot. Reads 0 after cold reset; reads 1 after firmware sets it. Sticky until next cold reset (preserved across warm resets).
0x30 OTP_LIFE_CYCLE reset 0x0 (reset mask 0xFFFFFF00) — Life cycle state. 8-bit (4-bit value differentially encoded). Read-through from OTP port; no reset.
  [7:0] value — 8-bit life cycle state from OTP. No reset; power-up value undefined.
0x34 OTP_DEMOTION_STATE reset 0x0 (reset mask 0xFFFFFFF0) — Demotion state. 2-bit, differentially encoded. Read-through from OTP port; no reset.
  [3:2] demote_2_value — 2-bit demotion 2 state from OTP. No reset; power-up value undefined.
  [1:0] demote_1_value — 2-bit demotion 1 state from OTP. No reset; power-up value undefined.
0x38 SRAM_EXEC_MODE access per field reset 0x0 — Execute-permission whitelist mode. Write-1-only (woset); cleared by warm or cold reset. 0=ROM executable; 1=write-locked SRAM regions executable, and the ROM lockout is armed. Set by ROM stack-less handover immediately before jumping to mutable firmware.
  [0] enable rw write-1-sets — Execute-permission mode: 0=ROM-only whitelist; 1=write-locked SRAM whitelist, arming the ROM lockout. Write 1 to set; write 0 has no effect. Warm reset domain: cleared by warm or cold reset.
0xB8 IRQ_ENTRY_ADDR rw reset 0x10 — Effective IRQ entry address for subsequent interrupts. Writable while unlocked; any 32-bit value accepted.
  [31:0] addr — IRQ handler entry PC. Reset matches ROM vector at 0x10. When locked, SW writes do not update storage.
0xBC IRQ_ENTRY_LOCK access per field reset 0x0 — Write-one-only lock for IRQ_ENTRY_ADDR. Separate readable register; cleared only on KM reset.
  [0] lock rw write-1-sets — Write 1 to set; write 0 has no effect; sticky until reset.
0x100 VUART_TX access per field reset 0x0 — Virtual UART transmit register. Write a byte to send to testbench. DATA_VALID is set on write and self-clears.
  [31] data_valid rw — Data valid strobe. Set by firmware on write, cleared by hardware after one cycle.
  [7:0] tx_byte rw — Byte to transmit (write to send character to testbench)
0x104 VUART_RX reset 0x0 — Virtual UART receive register. Testbench writes bytes here for firmware to read.
  [31] data_valid — RX data valid. Set by testbench, cleared by firmware read.
  [7:0] rx_byte — Received byte from testbench
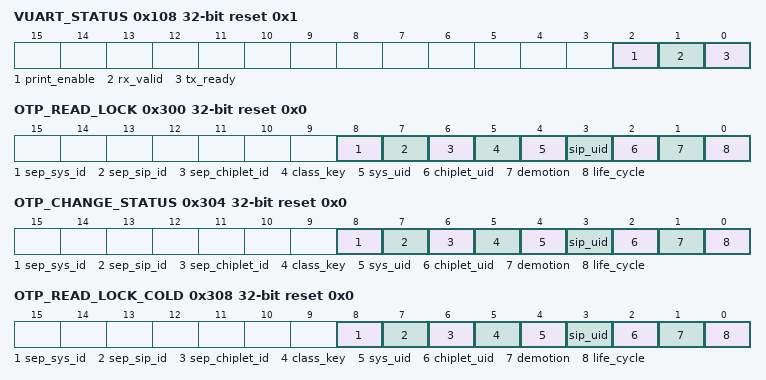
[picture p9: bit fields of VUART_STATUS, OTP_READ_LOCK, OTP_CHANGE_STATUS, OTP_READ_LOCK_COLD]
0x108 VUART_STATUS reset 0x1 — Virtual UART status register for flow control
  [2] print_enable — Enable VUART printing. Set by testbench to enable printf output. Disabled by default to save simulation time.
  [1] rx_valid — RX has valid data available
  [0] tx_ready — TX ready to accept data (always 1 in simulation)
0x110 TB_RESULT rw reset 0x0 — Test result register. Firmware writes 0=fail, 1=pass.
  [31:0] result — Test result: 0=fail, 1=pass
0x114 TB_SIGNATURE rw reset 0x0 — Test completion signature. Firmware writes 0x600D600D (pass) or 0xBADBADBA (fail).
  [31:0] signature — Completion signature value
0x118 TB_ERRCODE rw reset 0x0 — Test error code register. Firmware writes optional error code for debugging.
  [31:0] errcode — Error code value
0x11C TB_SUBTEST rw reset 0x0 — Current subtest number register. Firmware increments for each subtest.
  [31:0] subtest — Current subtest number
0x120 TB_CMD rw reset 0x0 — Testbench command register. Firmware writes command, testbench reads and clears.
  [31:0] cmd — Command code (0=NOP, 1=ROM_PARITY_EN, 2=ROM_PARITY_DIS, 3=SRAM_PARITY_EN, 4=SRAM_PARITY_DIS)
0x124 TB_CMD_ARG rw reset 0x0 — Testbench command argument register. Firmware writes optional argument.
  [31:0] arg — Command argument value
0x128 TB_CMD_STATUS rw reset 0x0 — Testbench command status register. Testbench writes status, firmware reads.
  [31:0] status — Command status: 0=IDLE, 1=ACK, 0xFFFFFFFF=ERR
0x12C TB_CMD_RESULT reset 0x0 — Testbench command result register. Testbench writes result value.
  [31:0] result — Command result value
0x1FC DEBUG reset 0xCAFEBEEF — Debug register with known constant value for verification
  [31:0] magic — Magic constant: 0xCAFEBEEF
{0x200+4i} OTP_CHIPLET_UID_VAL_{i} (i=0..7) — Dual-rail OTP readout word (value or complement half). Read-through from OTP port; no reset. Returns zero when the field's bit is set in either OTP_READ_LOCK or OTP_READ_LOCK_COLD.
  [31:0] value — 32-bit OTP word. No reset; power-up value undefined.
{0x220+4i} OTP_CHIPLET_UID_CPL_{i} (i=0..7) — Dual-rail OTP readout word (value or complement half). Read-through from OTP port; no reset. Returns zero when the field's bit is set in either OTP_READ_LOCK or OTP_READ_LOCK_COLD.
  [31:0] value — 32-bit OTP word. No reset; power-up value undefined.
{0x240+4i} OTP_SIP_UID_VAL_{i} (i=0..7) — Dual-rail OTP readout word (value or complement half). Read-through from OTP port; no reset. Returns zero when the field's bit is set in either OTP_READ_LOCK or OTP_READ_LOCK_COLD.
  [31:0] value — 32-bit OTP word. No reset; power-up value undefined.
{0x260+4i} OTP_SIP_UID_CPL_{i} (i=0..7) — Dual-rail OTP readout word (value or complement half). Read-through from OTP port; no reset. Returns zero when the field's bit is set in either OTP_READ_LOCK or OTP_READ_LOCK_COLD.
  [31:0] value — 32-bit OTP word. No reset; power-up value undefined.
{0x280+4i} OTP_SYS_UID_VAL_{i} (i=0..7) — Dual-rail OTP readout word (value or complement half). Read-through from OTP port; no reset. Returns zero when the field's bit is set in either OTP_READ_LOCK or OTP_READ_LOCK_COLD.
  [31:0] value — 32-bit OTP word. No reset; power-up value undefined.
{0x2A0+4i} OTP_SYS_UID_CPL_{i} (i=0..7) — Dual-rail OTP readout word (value or complement half). Read-through from OTP port; no reset. Returns zero when the field's bit is set in either OTP_READ_LOCK or OTP_READ_LOCK_COLD.
  [31:0] value — 32-bit OTP word. No reset; power-up value undefined.
{0x2C0+4i} OTP_CLASS_KEY_VAL_{i} (i=0..7) — Dual-rail OTP readout word (value or complement half). Read-through from OTP port; no reset. Returns zero when the field's bit is set in either OTP_READ_LOCK or OTP_READ_LOCK_COLD.
  [31:0] value — 32-bit OTP word. No reset; power-up value undefined.
{0x2E0+4i} OTP_CLASS_KEY_CPL_{i} (i=0..7) — Dual-rail OTP readout word (value or complement half). Read-through from OTP port; no reset. Returns zero when the field's bit is set in either OTP_READ_LOCK or OTP_READ_LOCK_COLD.
  [31:0] value — 32-bit OTP word. No reset; power-up value undefined.
0x300 OTP_READ_LOCK access per field reset 0x0 — OTP field warm-reset-domain read-lock bits. Write 1 to set; writing 0 has no effect. Locked reads of the corresponding OTP field return zero (effective lock = OTP_READ_LOCK | OTP_READ_LOCK_COLD). Warm-reset domain: cleared by warm or cold reset.
  [8] sep_sys_id rw write-1-sets — Lock OTP_SEP_SYS_ID_VAL/CPL reads (returns zero when locked)
  [7] sep_sip_id rw write-1-sets — Lock OTP_SEP_SIP_ID_VAL/CPL reads (returns zero when locked)
  [6] sep_chiplet_id rw write-1-sets — Lock OTP_SEP_CHIPLET_ID_VAL/CPL reads (returns zero when locked)
  [5] class_key rw write-1-sets — Lock OTP_CLASS_KEY_VAL/CPL reads (returns zero when locked)
  [4] sys_uid rw write-1-sets — Lock OTP_SYS_UID_VAL/CPL reads (returns zero when locked)
  [3] sip_uid rw write-1-sets — Lock OTP_SIP_UID_VAL/CPL reads (returns zero when locked)
  [2] chiplet_uid rw write-1-sets — Lock OTP_CHIPLET_UID_VAL/CPL reads (returns zero when locked)
  [1] demotion rw write-1-sets — Lock OTP_DEMOTION_STATE reads (returns zero when locked)
  [0] life_cycle rw write-1-sets — Lock OTP_LIFE_CYCLE reads (returns zero when locked)
0x304 OTP_CHANGE_STATUS access per field reset 0x0 — OTP field change status. A bit is set when the corresponding field's decoded value changes. Sticky, write 1 to clear. Valid after IRQ_STATUS.OTP_CHANGE fires.
  [8] sep_sys_id rw write-1-clears — OTP_SEP_SYS_ID value changed since last cycle. Sticky, write 1 to clear.
  [7] sep_sip_id rw write-1-clears — OTP_SEP_SIP_ID value changed since last cycle. Sticky, write 1 to clear.
  [6] sep_chiplet_id rw write-1-clears — OTP_SEP_CHIPLET_ID value changed since last cycle. Sticky, write 1 to clear.
  [5] class_key rw write-1-clears — OTP_CLASS_KEY value changed since last cycle. Sticky, write 1 to clear.
  [4] sys_uid rw write-1-clears — OTP_SYS_UID value changed since last cycle. Sticky, write 1 to clear.
  [3] sip_uid rw write-1-clears — OTP_SIP_UID value changed since last cycle. Sticky, write 1 to clear.
  [2] chiplet_uid rw write-1-clears — OTP_CHIPLET_UID value changed since last cycle. Sticky, write 1 to clear.
  [1] demotion rw write-1-clears — OTP_DEMOTION_STATE value changed since last cycle. Sticky, write 1 to clear.
  [0] life_cycle rw write-1-clears — OTP_LIFE_CYCLE value changed since last cycle. Sticky, write 1 to clear.
0x308 OTP_READ_LOCK_COLD access per field reset 0x0 — OTP field cold-reset-domain read-lock bits. Write 1 to set; writing 0 has no effect. Locked reads of the corresponding OTP field return zero (effective lock = OTP_READ_LOCK | OTP_READ_LOCK_COLD). Cold-reset domain: survives warm reset.
  [8] sep_sys_id rw write-1-sets — Cold-reset read-lock for OTP_SEP_SYS_ID_VAL/CPL. Effective lock = OTP_READ_LOCK.sep_sys_id | OTP_READ_LOCK_COLD.sep_sys_id.
  [7] sep_sip_id rw write-1-sets — Cold-reset read-lock for OTP_SEP_SIP_ID_VAL/CPL. Effective lock = OTP_READ_LOCK.sep_sip_id | OTP_READ_LOCK_COLD.sep_sip_id.
  [6] sep_chiplet_id rw write-1-sets — Cold-reset read-lock for OTP_SEP_CHIPLET_ID_VAL/CPL. Effective lock = OTP_READ_LOCK.sep_chiplet_id | OTP_READ_LOCK_COLD.sep_chiplet_id.
  [5] class_key rw write-1-sets — Cold-reset read-lock for OTP_CLASS_KEY_VAL/CPL. Effective lock = OTP_READ_LOCK.class_key | OTP_READ_LOCK_COLD.class_key.
  [4] sys_uid rw write-1-sets — Cold-reset read-lock for OTP_SYS_UID_VAL/CPL. Effective lock = OTP_READ_LOCK.sys_uid | OTP_READ_LOCK_COLD.sys_uid.
  [3] sip_uid rw write-1-sets — Cold-reset read-lock for OTP_SIP_UID_VAL/CPL. Effective lock = OTP_READ_LOCK.sip_uid | OTP_READ_LOCK_COLD.sip_uid.
  [2] chiplet_uid rw write-1-sets — Cold-reset read-lock for OTP_CHIPLET_UID_VAL/CPL. Effective lock = OTP_READ_LOCK.chiplet_uid | OTP_READ_LOCK_COLD.chiplet_uid.
  [1] demotion rw write-1-sets — Cold-reset read-lock for OTP_DEMOTION_STATE. Effective lock = OTP_READ_LOCK.demotion | OTP_READ_LOCK_COLD.demotion.
  [0] life_cycle rw write-1-sets — Cold-reset read-lock for OTP_LIFE_CYCLE. Effective lock = OTP_READ_LOCK.life_cycle | OTP_READ_LOCK_COLD.life_cycle.
{0x400+4i} OTP_SEP_CHIPLET_ID_VAL_{i} (i=0..7) — Dual-rail OTP readout word (value or complement half). Read-through from OTP port; no reset. Returns zero when the field's bit is set in either OTP_READ_LOCK or OTP_READ_LOCK_COLD.
  [31:0] value — 32-bit OTP word. No reset; power-up value undefined.
{0x420+4i} OTP_SEP_CHIPLET_ID_CPL_{i} (i=0..7) — Dual-rail OTP readout word (value or complement half). Read-through from OTP port; no reset. Returns zero when the field's bit is set in either OTP_READ_LOCK or OTP_READ_LOCK_COLD.
  [31:0] value — 32-bit OTP word. No reset; power-up value undefined.
{0x440+4i} OTP_SEP_SIP_ID_VAL_{i} (i=0..7) — Dual-rail OTP readout word (value or complement half). Read-through from OTP port; no reset. Returns zero when the field's bit is set in either OTP_READ_LOCK or OTP_READ_LOCK_COLD.
  [31:0] value — 32-bit OTP word. No reset; power-up value undefined.
{0x460+4i} OTP_SEP_SIP_ID_CPL_{i} (i=0..7) — Dual-rail OTP readout word (value or complement half). Read-through from OTP port; no reset. Returns zero when the field's bit is set in either OTP_READ_LOCK or OTP_READ_LOCK_COLD.
  [31:0] value — 32-bit OTP word. No reset; power-up value undefined.
{0x480+4i} OTP_SEP_SYS_ID_VAL_{i} (i=0..7) — Dual-rail OTP readout word (value or complement half). Read-through from OTP port; no reset. Returns zero when the field's bit is set in either OTP_READ_LOCK or OTP_READ_LOCK_COLD.
  [31:0] value — 32-bit OTP word. No reset; power-up value undefined.
{0x4A0+4i} OTP_SEP_SYS_ID_CPL_{i} (i=0..7) — Dual-rail OTP readout word (value or complement half). Read-through from OTP port; no reset. Returns zero when the field's bit is set in either OTP_READ_LOCK or OTP_READ_LOCK_COLD.
  [31:0] value — 32-bit OTP word. No reset; power-up value undefined.

## key_manager.drbg_sampler — DRBG random data interface and configuration/status registers
Base 0x00015000
0x00 DATA — One word of random data. Read triggers request or returns prefetch. Writes return SLVERR. No reset.
  [31:0] data — 32-bit random data from DRBG. No reset for security; power-up value undefined.
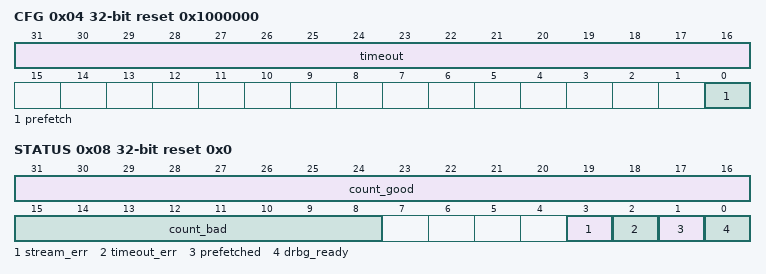
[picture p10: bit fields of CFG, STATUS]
0x04 CFG rw reset 0x1000000 — Configuration: PREFETCH enable, TIMEOUT cycles for active CPU read.
  [31:16] timeout — Cycles to wait for DRBG on active CPU read; 0 = disable. Default 256.
  [0] prefetch — Enable prefetch. When 0, prefetch data register is cleared.
0x08 STATUS access per field reset 0x0 — Status: DRBG_READY, PREFETCHED, TIMEOUT_ERR (W1C), STREAM_ERR (W1C), COUNT_BAD, COUNT_GOOD.
  [31:16] count_good rw — Counts only reads completed through ST_RESPOND, excluding prefetched words. Saturates at 0xFFFF. Writing any non-zero value clears the field to 0; writing 0 has no effect.
  [15:8] count_bad rw — Failed transactions (timeout or error). Saturates at 0xFF. Writing any non-zero value clears the field to 0; writing 0 has no effect.
  [3] stream_err rw write-1-clears — Set when there is an error on the DRBG AXI-Stream interface (e.g. TVALID deasserted before TREADY). Write 1 to clear.
  [2] timeout_err rw write-1-clears — Set when a DRBG read from the KM CPU times out. Write 1 to clear.
  [1] prefetched ro — Prefetched data available
  [0] drbg_ready ro — TVALID asserted from DRBG
0x0C PREFETCH_DATA — Prefetched word (read-only, for debugging). Cleared when PREFETCH=0. No reset; power-up undefined.
  [31:0] data — Prefetched 32-bit random data. No reset for security; power-up value undefined.

## key_manager.otbn_wrapper_key — Key storage registers for the OTBN sideload interface. Written by Key Manager CPU, drives keymgr_key_i on the OT OTBN core.
Base 0x00018000
{0x0+4i} KEY_SHARE0[{i}] (i=0..11) wo — One 32-bit word of key data. Write-only; reads return 0. No reset; powers up with undefined value.
  [31:0] data — 32-bit key data word. Write-only for security.
{0x30+4i} KEY_SHARE1[{i}] (i=0..11) wo — One 32-bit word of key data. Write-only; reads return 0. No reset; powers up with undefined value.
  [31:0] data — 32-bit key data word. Write-only for security.
0x60 KEY_CTRL access per field reset 0x0 — Key control register. Writing KEY_VALID=1 asserts the sideload valid signal to the OTBN core.
  [0] key_valid rw — When 1, asserts keymgr_key_i.valid to indicate key is loaded. Write 0 to invalidate the current key.

## key_manager.aes_wrapper_key — Key storage registers for the AES sideload interface. Written by Key Manager CPU, drives keymgr_key_i on the OT AES core.
Base 0x00019000
{0x0+4i} KEY_SHARE0[{i}] (i=0..7) wo — One 32-bit word of key data. Write-only; reads return 0. No reset; powers up with undefined value.
  [31:0] data — 32-bit key data word. Write-only for security.
{0x20+4i} KEY_SHARE1[{i}] (i=0..7) wo — One 32-bit word of key data. Write-only; reads return 0. No reset; powers up with undefined value.
  [31:0] data — 32-bit key data word. Write-only for security.
0x40 KEY_CTRL access per field reset 0x0 — Key control register. Writing KEY_VALID=1 asserts the sideload valid signal to the AES core.
  [0] key_valid rw — When 1, asserts keymgr_key_i.valid to indicate key is loaded. Write 0 to invalidate the current key.

## key_manager.kmac_wrapper_key — Key storage registers for the KMAC sideload interface. Written by Key Manager CPU, drives keymgr_key_i on the OT KMAC core.
Base 0x0001A000
Registers as key_manager.aes_wrapper_key; these are added or differ:
0x40 KEY_CTRL access per field reset 0x0 — Key control register. Writing KEY_VALID=1 asserts the sideload valid signal to the KMAC core.
  [0] key_valid rw — When 1, asserts keymgr_key_i.valid to indicate key is loaded. Write 0 to invalidate the current key.

## key_manager.hmac_wrapper_key — Key storage registers for the HMAC sideload interface. Written by Key Manager CPU, drives keymgr_key_i on the OT HMAC core.
Base 0x0001B000
Registers as key_manager.aes_wrapper_key; these are added or differ:
0x40 KEY_CTRL access per field reset 0x0 — Key control register. Writing KEY_VALID=1 asserts the sideload valid signal to the HMAC core.
  [0] key_valid rw — When 1, asserts keymgr_key_i.valid to indicate key is loaded. Write 0 to invalidate the current key.

## key_manager.abr_wrapper_key — Single AXI4-Lite window for all KM sideload interfaces to Adams Bridge. Contains four dual-share secret-seed inputs and one shared-key output.
Base 0x0001C000
0x00 MLDSA_SEED group — Dual-share 256-bit secret seed (write-only) + key_valid flag. Layout identical to aes_wrapper_key for firmware reuse.
  {0x0+4j} KEY_SHARE0[{j}] (j=0..7) wo — One 32-bit word of key data. Write-only; reads return 0. No reset; powers up with undefined value.
    [31:0] data — 32-bit key data word. Write-only for security.
  {0x20+4j} KEY_SHARE1[{j}] (j=0..7) wo — One 32-bit word of key data. Write-only; reads return 0. No reset; powers up with undefined value.
    [31:0] data — 32-bit key data word. Write-only for security.
  0x40 KEY_CTRL access per field reset 0x0 — Seed control register. Writing KEY_VALID=1 marks the seed as loaded. Write 0 to invalidate. The KV shim gates the AB kv_read response on this bit.
    [0] key_valid rw — When 1, the seed is loaded and the KV shim will serve it to Adams Bridge. Write 0 to invalidate and allow a new seed to be written.
0x100 MLKEM_SEED_D group — Dual-share 256-bit secret seed (write-only) + key_valid flag. Layout identical to aes_wrapper_key for firmware reuse.
  {0x0+4j} KEY_SHARE0[{j}] (j=0..7) wo — One 32-bit word of key data. Write-only; reads return 0. No reset; powers up with undefined value.
    [31:0] data — 32-bit key data word. Write-only for security.
  {0x20+4j} KEY_SHARE1[{j}] (j=0..7) wo — One 32-bit word of key data. Write-only; reads return 0. No reset; powers up with undefined value.
    [31:0] data — 32-bit key data word. Write-only for security.
  0x40 KEY_CTRL access per field reset 0x0 — Seed control register. Writing KEY_VALID=1 marks the seed as loaded. Write 0 to invalidate. The KV shim gates the AB kv_read response on this bit.
    fields as MLDSA_SEED.KEY_CTRL
0x200 MLKEM_SEED_Z group — Dual-share 256-bit secret seed (write-only) + key_valid flag. Layout identical to aes_wrapper_key for firmware reuse.
  {0x0+4j} KEY_SHARE0[{j}] (j=0..7) wo — One 32-bit word of key data. Write-only; reads return 0. No reset; powers up with undefined value.
    [31:0] data — 32-bit key data word. Write-only for security.
  {0x20+4j} KEY_SHARE1[{j}] (j=0..7) wo — One 32-bit word of key data. Write-only; reads return 0. No reset; powers up with undefined value.
    [31:0] data — 32-bit key data word. Write-only for security.
  0x40 KEY_CTRL access per field reset 0x0 — Seed control register. Writing KEY_VALID=1 marks the seed as loaded. Write 0 to invalidate. The KV shim gates the AB kv_read response on this bit.
    fields as MLDSA_SEED.KEY_CTRL
0x300 MLKEM_MSG group — Dual-share 256-bit secret seed (write-only) + key_valid flag. Layout identical to aes_wrapper_key for firmware reuse.
  {0x0+4j} KEY_SHARE0[{j}] (j=0..7) wo — One 32-bit word of key data. Write-only; reads return 0. No reset; powers up with undefined value.
    [31:0] data — 32-bit key data word. Write-only for security.
  {0x20+4j} KEY_SHARE1[{j}] (j=0..7) wo — One 32-bit word of key data. Write-only; reads return 0. No reset; powers up with undefined value.
    [31:0] data — 32-bit key data word. Write-only for security.
  0x40 KEY_CTRL access per field reset 0x0 — Seed control register. Writing KEY_VALID=1 marks the seed as loaded. Write 0 to invalidate. The KV shim gates the AB kv_read response on this bit.
    fields as MLDSA_SEED.KEY_CTRL
0x400 MLKEM_SHARED_KEY group — 256-bit ML-KEM shared key output from Adams Bridge. Hardware writes KEY[*] and sets KEY_CTRL.KEY_VALID when ready. Firmware reads KEY[*] then writes KEY_CTRL=0 to consume/zeroize. IRQ_STATUS is a sticky W1C bit set by hardware on the key-ready event; the masked CPU interrupt is IRQ_STATUS & IRQ_ENABLE.
  {0x0+4j} KEY[{j}] (j=0..7) reset 0x0 — One 32-bit word of ML-KEM shared key output. Written by hardware when key is ready; read by KM firmware to consume. Hardware clears all words to 0 when KEY_CTRL.KEY_VALID is cleared (via hwclr).
    [31:0] data — 32-bit shared-key word. Hardware writes on key-ready event; hardware clears to 0 on key-consume event (KEY_VALID cleared).
  0x20 KEY_CTRL access per field reset 0x0 — Shared-key control. HW sets KEY_VALID when a new key is ready. Firmware writes 0 to clear (consume and zeroize).
    [0] key_valid rw write-0-clears — 1 = shared key is valid and ready for firmware consumption. Hardware sets this bit on key-ready event. Write 0 to clear; write 1 has no effect (software cannot set this bit).
  0x24 IRQ_STATUS access per field reset 0x0 — Interrupt status for ML-KEM shared key. Sticky bit set by hardware when a new shared key becomes valid; cleared by writing 1.
    [0] key_valid rw write-1-clears — ML-KEM shared key valid. Sticky, write 1 to clear.
  0x28 IRQ_ENABLE access per field reset 0x0 — Interrupt enable for ML-KEM shared key. Mask for the PicoRV32 IRQ vector bit driven by the shared-key-valid event.
    [0] key_valid_en rw — 1 = enable PicoRV32 IRQ when ML-KEM shared key is valid. 0 = mask the interrupt (KEY_CTRL.KEY_VALID can still be polled).

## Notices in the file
SPDX-License-Identifier: Apache-2.0
SPDX-FileCopyrightText: 2026 Tenstorrent USA, Inc.
